# TREMO register map
File version: 1.6.2
CPU: CM4 r0p1, little endian, MPU, FPU, 3 interrupt priority bits
Registers are 32-bit, read-write, reset 0x0 unless marked. A register's access mark holds for its fields unless they carry their own. Offsets are from the block's base; [hi:lo] are bit positions; {n}, {i} and the like mark numbered series.

## CRC
Base 0x40022000
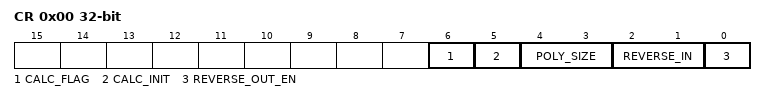
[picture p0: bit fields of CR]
0x00 CR — control register
  [6] CALC_FLAG, [5] CALC_INIT, [4:3] POLY_SIZE, [2:1] REVERSE_IN, [0] REVERSE_OUT_EN
0x04 DR — data register
  [31:0] DATA
0x08 INIT — init value register
0x0C POLY — polynomial register

## SYSCFG — System configuration
Base 0x40001000
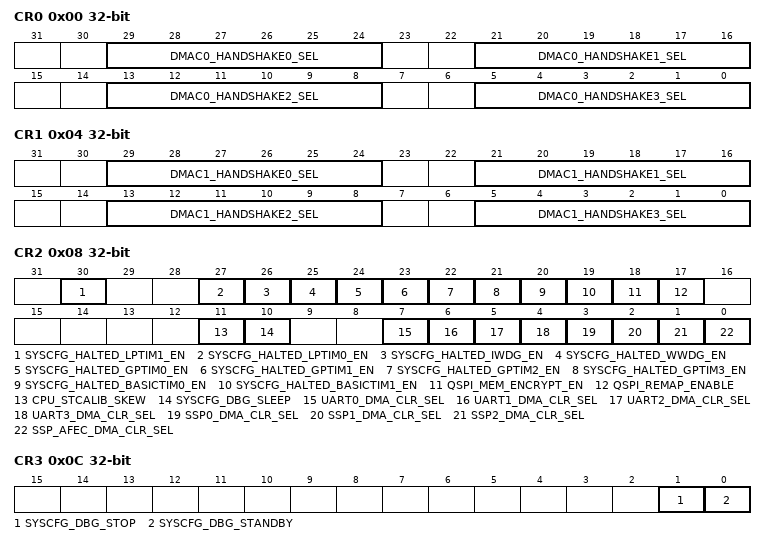
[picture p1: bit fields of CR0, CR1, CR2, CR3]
0x00 CR0 — control register 0
  [29-8n:24-8n] DMAC0_HANDSHAKE{n}_SEL (n=0..3) — DMAC0 HANDSHAKE{n} selection
0x04 CR1 — control register 1
  [29-8n:24-8n] DMAC1_HANDSHAKE{n}_SEL (n=0..3) — DMAC1 HANDSHAKE{n} selection
0x08 CR2 — control register 2
  [30] SYSCFG_HALTED_LPTIM1_EN — LPTIM1 counter is stopped when the core is halted
  [27] SYSCFG_HALTED_LPTIM0_EN — LPTIM0 counter is stopped when the core is halted
  [26] SYSCFG_HALTED_IWDG_EN — independent watchdog counter is stopped when the core is halted
  [25] SYSCFG_HALTED_WWDG_EN — window watchdog counter is stopped when the core is halted
  [24-n] SYSCFG_HALTED_GPTIM{n}_EN (n=0..3) — GPTIM{n} counter is stopped when the core is halted
  [20] SYSCFG_HALTED_BASICTIM0_EN — BASICTIM0 counter is stopped when the core is halted
  [19] SYSCFG_HALTED_BASICTIM1_EN — BASICTIM1 counter is stopped when the core is halted
  [18] QSPI_MEM_ENCRYPT_EN — QSPI memory encryption enable
  [17] QSPI_REMAP_ENABLE — QSPI remap function enable
  [11] CPU_STCALIB_SKEW — CPU SysTick skew configuration
  [10] SYSCFG_DBG_SLEEP — to allow a debug connection in Deepsleep mode
  [7-n] UART{n}_DMA_CLR_SEL (n=0..3) — UART{n} DMA_CLR signal selection
  [3] SSP0_DMA_CLR_SEL — SSP0 DMA_CLR signal selection
  [2] SSP1_DMA_CLR_SEL — SSP1 DMA_CLR signal selection
  [1] SSP2_DMA_CLR_SEL — SSP2 DMA_CLR signal selection
  [0] SSP_AFEC_DMA_CLR_SEL — SSP (for afec) DMA_CLR signal selection
0x0C CR3 — control register 3
  [1] SYSCFG_DBG_STOP — allow a debug connection in Stop mode
  [0] SYSCFG_DBG_STANDBY — allow a debug connection in Standby mode
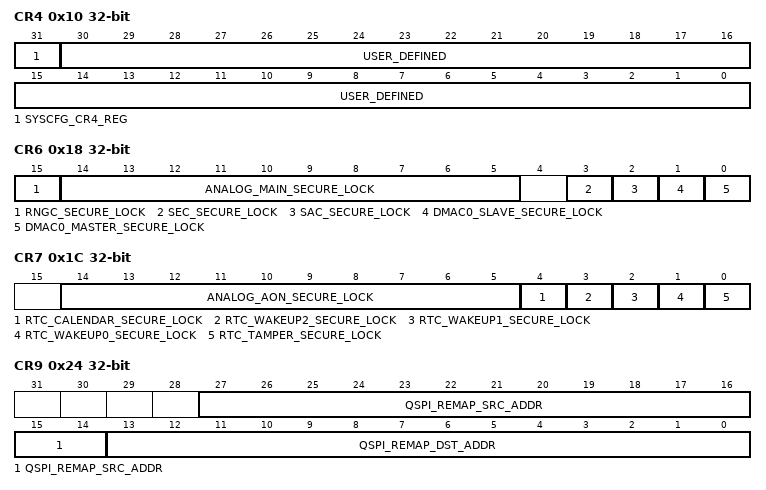
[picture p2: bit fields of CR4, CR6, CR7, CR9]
0x10 CR4 — control register 4
  [31] SYSCFG_CR4_REG — LPTIM1 IN2 remapping enable
  [30:0] USER_DEFINED
0x14 CR5 — control register 5
  [31:0] USER_DEFINED
0x18 CR6 — control register 6
  [15] RNGC_SECURE_LOCK — RNGC security lock
  [14:5] ANALOG_MAIN_SECURE_LOCK — Security lock for main domain configuration of AFEC
  [3] SEC_SECURE_LOCK — SEC security lock
  [2] SAC_SECURE_LOCK — SAC security lock
  [1] DMAC0_SLAVE_SECURE_LOCK — DMAC0 slave interface security lock
  [0] DMAC0_MASTER_SECURE_LOCK — DMAC0 master interface security lock
0x1C CR7 — control register 7
  [14:5] ANALOG_AON_SECURE_LOCK — Security lock for AON domain configuration of AFEC
  [4] RTC_CALENDAR_SECURE_LOCK — Calendar configuration security lock in RTC
  [3] RTC_WAKEUP2_SECURE_LOCK — Wakeup2 configuration security lock in RTC
  [2] RTC_WAKEUP1_SECURE_LOCK — Wakeup1 configuration security lock in RTC
  [1] RTC_WAKEUP0_SECURE_LOCK — Tamper configuration security lock in RTC
  [0] RTC_TAMPER_SECURE_LOCK — Tamper configuration security lock in RTC
0x20 CR8 — control register 8
  [31:0] QSPI_MEM_ENCRYPT_KEY — Encryption key for QSPI memory
0x24 CR9 — control register 9
  [27:14] QSPI_REMAP_SRC_ADDR — QSPI remap source address
  [13:0] QSPI_REMAP_DST_ADDR — QSPI remap destination address
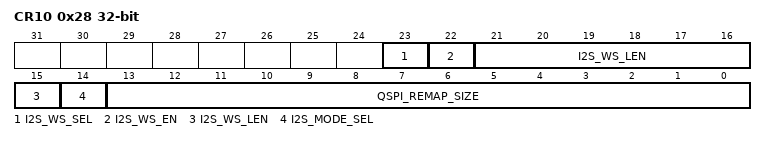
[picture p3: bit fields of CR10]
0x28 CR10 — control register 10
  [23] I2S_WS_SEL — I2S WS output delay enable
  [22] I2S_WS_EN — I2S WS enable
  [21:15] I2S_WS_LEN — I2S main interface resolution configuration
  [14] I2S_MODE_SEL — I2S works in master or slave mode
  [13:0] QSPI_REMAP_SIZE — Address space for QSPI remapping

## PWR — Power control
Base 0x40001800
0x00 CR0 — control register 0
  [31:0] CR
0x04 CR1 — control register 1
  [31:0] CR
0x08 SR0 — status register 0
  [31:0] SR
0x0C SR1 — status register 1
  [31:0] SR
{0x8+4i} CR{i} (i=2..5) — control register {i}
  [31:0] CR
